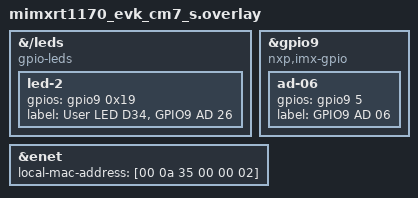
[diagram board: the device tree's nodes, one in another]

&{/leds} {
	compatible = "gpio-leds";
	led-2 {
		gpios = < &gpio9 0x19 GPIO_ACTIVE_HIGH >;
		label = "User LED D34, GPIO9 AD 26";
		status = "okay";
	};
};

&gpio9 {
	compatible = "nxp,imx-gpio";
	ad-06 {
		gpios = < &gpio9 5 GPIO_ACTIVE_HIGH >;
		label = "GPIO9 AD 06";
		status = "okay";
	};
};
&enet {
	local-mac-address = [00 0a 35 00 00 02];
	status = "okay";
};
